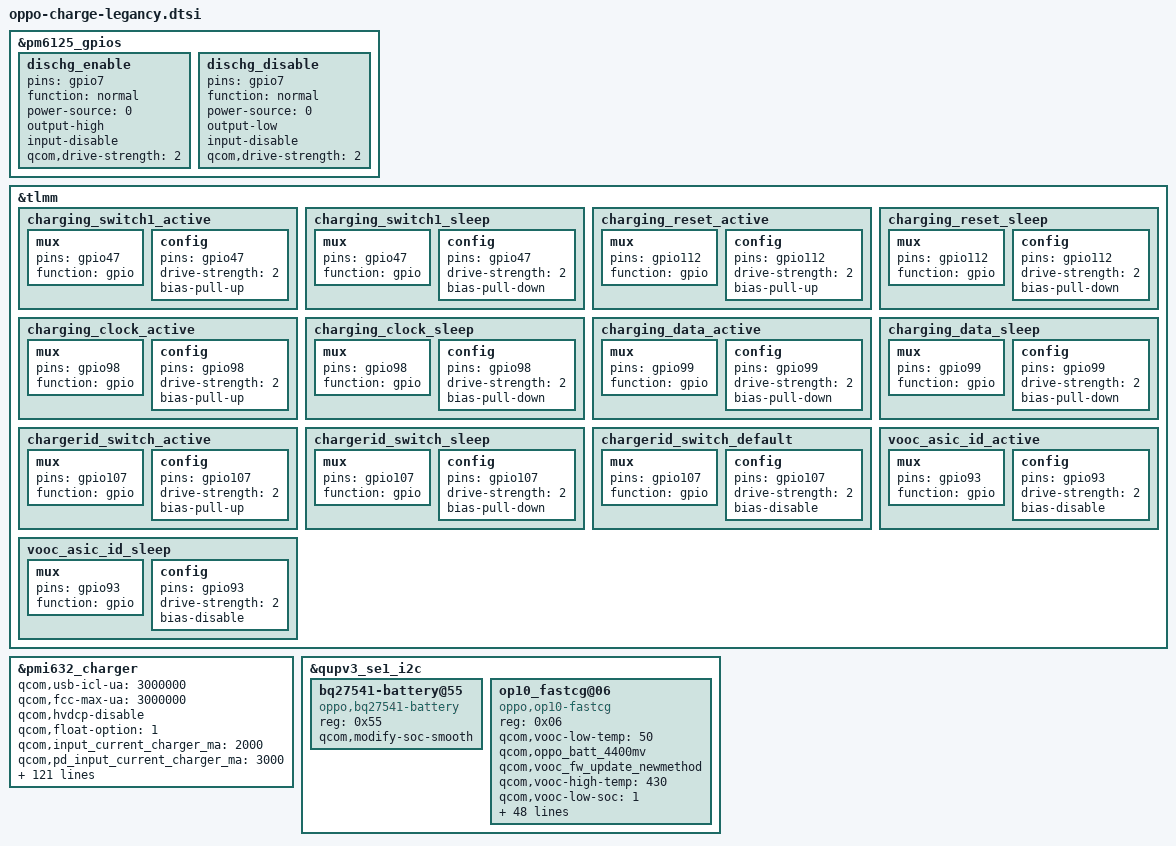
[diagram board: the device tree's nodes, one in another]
/**********************************************************************************
* Copyright (c)  2008-2019  Guangdong OPPO Mobile Comm Corp., Ltd
* VENDOR_EDIT
* Description: OPPO Charge Module Device Tree
*
* Version: 1.0
* Date: 2019-06-10
* Author: Yichun.Chen
*
* ------------------------------ Revision History: --------------------------------
* <version>           <date>                <author>                            <desc>
* Revision 1.0       2019-06-10            Yichun.Chen             Created for new architecture
***********************************************************************************/
&pm6125_gpios {
	dischg_enable: dischg_enable {
		pins = "gpio7";
		function = "normal";
		power-source = <0>;
		output-high;
		input-disable;
		qcom,drive-strength = <2>;
	};

	dischg_disable: dischg_disable {
		pins = "gpio7";
		function = "normal";
		power-source = <0>;
		output-low;
		input-disable;
		qcom,drive-strength = <2>;
	};
};

&tlmm {
			charging_switch1_active: charging_switch1_active {
				mux {
					pins = "gpio47";
					function = "gpio";
				};

				config {
					pins = "gpio47";
					drive-strength = <2>;
					bias-pull-up;
				};
			};

			charging_switch1_sleep: charging_switch1_sleep {
				mux {
					pins = "gpio47";
					function = "gpio";
				};

				config {
					pins = "gpio47";
					drive-strength = <2>;
					bias-pull-down;
				};
			};

			charging_reset_active: charging_reset_active {
				mux {
					pins = "gpio112";
					function = "gpio";
				};

				config {
					pins = "gpio112";
					drive-strength = <2>;
					bias-pull-up;
				};
			};

			charging_reset_sleep: charging_reset_sleep {
				mux {
					pins = "gpio112";
					function = "gpio";
				};

				config {
					pins = "gpio112";
					drive-strength = <2>;
					bias-pull-down;
				};
			};

			charging_clock_active: charging_clock_active {
				mux {
					pins = "gpio98";
					function = "gpio";
				};

				config {
					pins = "gpio98";
					drive-strength = <2>;
					bias-pull-up;
				};
			};

			charging_clock_sleep: charging_clock_sleep {
				mux {
					pins = "gpio98";
					function = "gpio";
				};

				config {
					pins = "gpio98";
					drive-strength = <2>;
					bias-pull-down;
				};
			};

			charging_data_active: charging_data_active {
				mux {
					pins = "gpio99";
					function = "gpio";
				};

				config {
					pins = "gpio99";
					drive-strength = <2>;
					bias-pull-down;
				};
			};

			charging_data_sleep: charging_data_sleep {
				mux {
					pins = "gpio99";
					function = "gpio";
				};

				config {
					pins = "gpio99";
					drive-strength = <2>;
					bias-pull-down;
				};
			};

			chargerid_switch_active: chargerid_switch_active {
				mux {
					pins = "gpio107";
					function = "gpio";
				};

				config {
					pins = "gpio107";
					drive-strength = <2>;
					bias-pull-up;
				};
			};

			chargerid_switch_sleep: chargerid_switch_sleep {
				mux {
					pins = "gpio107";
					function = "gpio";
				};

				config {
					pins = "gpio107";
					drive-strength = <2>;
					bias-pull-down;
				};
			};

			chargerid_switch_default: chargerid_switch_default {
				mux {
					pins = "gpio107";
					function = "gpio";
				};

				config {
					pins = "gpio107";
					drive-strength = <2>;
					bias-disable; /* NO PULL */
				};
			};
//#ifdef ODM_HQ_EDIT
/*zoutao@ODM_HQ.Charge add rk826 vooc 2020/06/10*/
			vooc_asic_id_active: vooc_asic_id_active {
				mux {
					pins = "gpio93";
					function = "gpio";
				};

				config {
					pins = "gpio93";
					drive-strength = <2>;
					bias-disable; /* NO PULL */
				};
			};

			vooc_asic_id_sleep: vooc_asic_id_sleep {
				mux {
					pins = "gpio93";
					function = "gpio";
				};

				config {
					pins = "gpio93";
					drive-strength = <2>;
					bias-disable; /* NO PULL */
				};
			};
//#endif
};

&pmi632_charger {

	//test_bob-supply = <&pm8150a_bob>;
	qcom,usb-icl-ua = <3000000>;
	qcom,fcc-max-ua = <3000000>;
	//qcom,fv-max-uv = <4373000>;
	qcom,hvdcp-disable;
	//io-channels = <&pm8150b_vadc ADC_GPIO3>;
	//io-channel-names = "chgID_voltage_adc";
	//qcom,otg-cl-ua = <2000000>;
	qcom,float-option = <1>;

	//for oppo chg framework:
	qcom,input_current_charger_ma = <2000>;
	qcom,pd_input_current_charger_ma = <3000>;
	qcom,input_current_usb_ma = <500>;

	qcom,input_current_led_ma = <1200>;
	qcom,input_current_led_ma_high = <1200>;
	qcom,input_current_led_ma_warm = <1500>;
	qcom,input_current_led_ma_normal = <2000>;

	qcom,input_current_camera_ma = <1200>;
	qcom,input_current_cdp_ma = <1500>;
	//qcom,input_current_led_ma_overtemp = <900>;
	qcom,overtemp_bat_decidegc = <350>;
	qcom,iterm_disabled = <0>;
	sw_full_count = <25>;
	qcom,iterm_ma = <210>;
	qcom,recharge-mv = <100>;
	qcom,batt_capacity_mah = <4015>;/*typical capacity*/
	//qcom,batt_capacity_mah = <3950>; /*rated capacity*/

	qcom,removed_bat_decidegc = <190>;	/* < -19C */

	qcom,cold_bat_decidegc = <20>;		/* -2C ~ 0C */
	qcom,temp_cold_vfloat_mv = <3980>;
	qcom,temp_cold_fastchg_current_ma = <314>;

	qcom,little_cold_bat_decidegc = <0>;	/* 0C ~ 5C */
	qcom,temp_little_cold_vfloat_mv = <4435>;
	qcom,temp_little_cold_fastchg_current_ma_high = <2200>;
	qcom,temp_little_cold_fastchg_current_ma_low = <1850>;
	qcom,pd_temp_little_cold_fastchg_current_ma_high = <2650>;
	qcom,pd_temp_little_cold_fastchg_current_ma_low = <1850>;
	qcom,temp_little_cold_fastchg_current_ma = <1850>;

	qcom,cool_bat_decidegc = <50>;		/* 5C~12C */
	qcom,temp_cool_vfloat_mv = <4435>;
	qcom,temp_cool_fastchg_current_ma_high = <2200>;
	qcom,temp_cool_fastchg_current_ma_low = <2200>;
	qcom,pd_temp_cool_fastchg_current_ma_high = <3300>;
	qcom,pd_temp_cool_fastchg_current_ma_low = <2650>;

	qcom,little_cool_bat_decidegc = <120>;	/*12C~16C*/
	qcom,temp_little_cool_vfloat_mv = <4435>;
	qcom,temp_little_cool_fastchg_current_ma = <2200>;
	qcom,pd_temp_little_cool_fastchg_current_ma = <3300>;

	qcom,normal_bat_decidegc = <160>;	/*16C~44C*/
	qcom,temp_normal_fastchg_current_ma = <2200>;
	qcom,pd_temp_normal_fastchg_current_ma = <3300>;
	qcom,temp_normal_vfloat_mv = <4435>;

	qcom,warm_bat_decidegc = <450>;		/*44C~53C*/ /*8pin Bat Vooc project need add 3 degree C*/
	qcom,temp_warm_vfloat_mv = <4130>;
	qcom,temp_warm_fastchg_current_ma = <1100>;
	qcom,pd_temp_warm_fastchg_current_ma = <1100>;
	qcom,temp_warm_fastchg_current_ma_led_on = <500>;

	qcom,hot_bat_decidegc = <530>;

	qcom,non_standard_vfloat_mv = <3980>;
	qcom,non_standard_fastchg_current_ma = <512>;
	qcom,short_c_bat_cv_mv = <4330>;
	qcom,short_c_bat_vfloat_mv = <3800>;
	qcom,short_c_bat_fastchg_current_ma = <512>;

	qcom,cold_vfloat_sw_limit = <3980>;
	qcom,little_cold_vfloat_sw_limit = <4385>;
	qcom,cool_vfloat_sw_limit = <4385>;
	qcom,little_cool_vfloat_sw_limit = <4385>;
	qcom,normal_vfloat_sw_limit = <4385>;
	qcom,warm_vfloat_sw_limit = <4130>;
	qcom,non_standard_vfloat_sw_limit = <3930>;
	qcom,short_c_bat_vfloat_sw_limit = <3750>;

	qcom,max_chg_time_sec = <57600>;
	qcom,charger_hv_thr = <5900>;
	qcom,charger_recv_thr = <5500>;
	qcom,charger_lv_thr = <3400>;
	qcom,vbatt_full_thr = <4400>;
	qcom,vbatt_hv_thr = <4550>;
	qcom,vfloat_step_mv = <8>;
	qcom,non_standard_vfloat_over_sw_limit = <3990>;
	qcom,cold_vfloat_over_sw_limit = <3990>;
	qcom,little_cold_vfloat_over_sw_limit = <4445>;
	qcom,cool_vfloat_over_sw_limit = <4445>;
	qcom,little_cool_vfloat_over_sw_limit = <4445>;
	qcom,normal_vfloat_over_sw_limit = <4445>;
	qcom,warm_vfloat_over_sw_limit = <4140>;

	qcom,vbatt_power_off = <3300>;
	qcom,vbatt_soc_1 = <3410>;
	qcom,vooc_project = <1>;
	qcom,vbatt_num = <1>;
	//qcom,new_ui_warning_support;
	qcom,ffc_support;

	qcom,normal_vterm_hw_inc = <18>;
	qcom,non_normal_vterm_hw_inc = <18>;

	qcom,ff1_normal_fastchg_ma = <1500>;
	qcom,ff1_exit_step_ma = <550>;
	qcom,ff1_warm_exit_step_ma = <500>;
	qcom,ffc2_normal_fastchg_ma = <1100>;/*12C~35c*/
	qcom,ffc2_temp_warm_decidegc = <350>;
	qcom,ffc2_warm_fastchg_ma = <1150>;/*35C~40c*/
	qcom,ffc2_temp_high_decidegc = <400>;
	qcom,ffc2_temp_low_decidegc = <120>;
	qcom,ffc2_exit_step_ma = <150>;

	qcom,ffc_normal_vfloat_sw_limit = <4475>;
	qcom,ffc_temp_normal_vfloat_mv = <4550>;
	qcom,ffc_normal_vfloat_over_sw_limit = <4550>;

	qcom,default_iterm_ma = <210>;
	qcom,default_temp_normal_fastchg_current_ma = <2200>;
	qcom,default_normal_vfloat_sw_limit = <4385>;
	qcom,default_temp_normal_vfloat_mv = <4435>;
	qcom,default_normal_vfloat_over_sw_limit = <4445>;

	qcom,default_temp_little_cool_fastchg_current_ma = <2200>;
	qcom,default_little_cool_vfloat_sw_limit = <4385>;
	qcom,default_temp_little_cool_vfloat_mv = <4435>;
	qcom,default_little_cool_vfloat_over_sw_limit = <4445>;

	///qcom,offset_temp = <30>;
	//for control:
	//qcom,suspend_after_full;
	qcom,check_batt_full_by_sw;
	qcom,external_gauge;
	qcom,chg_ctrl_by_lcd;
	qcom,chg_ctrl_by_camera;
	qcom,sw_vfloat_over_protect_enable;
	qcom,lpd-disable;

	qcom,chargerid_switch-gpio = <&tlmm 107 0x00>;
	qcom,dischg-gpio = <&pm6125_gpios 7 0x00>;

	pinctrl-names = "chargerid_switch_active", "chargerid_switch_sleep", "chargerid_switch_default",
					"dischg_enable", "dischg_disable";

	pinctrl-0 = <&chargerid_switch_active>;
	pinctrl-1 = <&chargerid_switch_sleep>;
	pinctrl-2 = <&chargerid_switch_default>;
	pinctrl-3 = <&dischg_enable>;
	pinctrl-4 = <&dischg_disable>;
};

&qupv3_se1_i2c {
	status = "okay";
	//qcom,clk-freq-out = <100000>;

	bq27541-battery@55 {
		status = "okay";
		compatible = "oppo,bq27541-battery";
		reg = <0x55>;
		qcom,modify-soc-smooth;
		//qcom,battery-full-param;//only for wite battery full param in guage dirver probe on 7250 platform
	};

	op10_fastcg@06{
		status = "okay";
		compatible = "oppo,op10-fastcg";
		reg = <0x06>;
		qcom,vooc-low-temp = <50>;
		qcom,oppo_batt_4400mv;
//#ifdef ODM_HQ_EDIT
/*zoutao@ODM_HQ.Charge vooc firmware update newmethod 2020/07/08*/
		qcom,vooc_fw_update_newmethod;
//#endif
		///qcom,vooc-fw-type = <0x22>;//5A
		qcom,vooc-high-temp = <430>;
		qcom,vooc-low-soc = <1>;
		qcom,vooc-high-soc = <85>;
		qcom,vooc-fw-type = <3>;

		qcom,vooc_multistep_adjust_current_support;
		qcom,vooc_multistep_initial_batt_temp = <1000>;
		qcom,vooc_strategy_normal_current = <0x06>;

		qcom,vooc-normal-to-little-cool-current = <0x04>;
		qcom,vooc_strategy1_batt_high_temp0 = <400>;
		qcom,vooc_strategy1_batt_high_temp1 = <425>;
		qcom,vooc_strategy1_batt_high_temp2 = <435>;
		qcom,vooc_strategy1_batt_low_temp2 = <430>;
		qcom,vooc_strategy1_batt_low_temp1 = <410>;
		qcom,vooc_strategy1_batt_low_temp0 = <390>;

		qcom,vooc_strategy1_high_current0 = <0x04>;//4A
		qcom,vooc_strategy1_high_current1 = <0x03>;//3A
		qcom,vooc_strategy1_high_current2 = <0x02>;//2A
		qcom,vooc_strategy1_low_current2 = <0x03>;//3A
		qcom,vooc_strategy1_low_current1 = <0x05>;//5A
		qcom,vooc_strategy1_low_current0 = <0x06>;//6A

		qcom,vooc_strategy2_batt_up_temp1 = <370>;
		qcom,vooc_strategy2_batt_up_down_temp2 = <380>;
		qcom,vooc_strategy2_batt_up_temp3 = <390>;
		qcom,vooc_strategy2_batt_up_down_temp4 = <395>;
		qcom,vooc_strategy2_batt_up_temp5 = <400>;
		qcom,vooc_strategy2_batt_up_temp6 = <415>;
		qcom,vooc_strategy2_high0_current = <0x06>;
		qcom,vooc_strategy2_high1_current = <0x06>;
		qcom,vooc_strategy2_high2_current = <0x06>;
		qcom,vooc_strategy2_high3_current = <0x06>;

		pinctrl-names = "switch1_act_switch2_act", "switch1_sleep_switch2_sleep",
						"switch1_act_switch3_act", "switch1_sleep_switch3_sleep",
						"switch1_act_switch2_sleep", "switch1_sleep_switch2_act",
						"clock_active","clock_sleep",
						"data_active","data_sleep",
						"reset_active","reset_sleep",
						"vooc_asic_id_active","vooc_asic_id_sleep";
		pinctrl-0 = <&charging_switch1_active>;
		pinctrl-1 = <&charging_switch1_sleep >;
		pinctrl-2 = <&charging_switch1_active>;
		pinctrl-3 = <&charging_switch1_sleep >;
		pinctrl-4 = <&charging_switch1_active>;
		pinctrl-5 = <&charging_switch1_sleep>;
		pinctrl-6 = <&charging_clock_active >;
		pinctrl-7 = <&charging_clock_sleep >;
		pinctrl-8 = <&charging_data_active >;
		pinctrl-9 = <&charging_data_sleep >;
		pinctrl-10 = <&charging_reset_active >;
		pinctrl-11 = <&charging_reset_sleep >;
		pinctrl-12 = <&vooc_asic_id_active >;
		pinctrl-13 = <&vooc_asic_id_sleep >;

		qcom,charging_switch1-gpio = <&tlmm 47 0x00>;
		qcom,charging_switch1_ctr1-gpio = <&tlmm 52 0x00>;
		//qcom,charging_switch2-gpio = <&tlmm 113 0x00>;
		//qcom,charging_switch3-gpio = <&tlmm 38 0x00>;

		qcom,charging_reset-gpio = <&tlmm 112 0x00>;
		qcom,charging_clock-gpio = <&tlmm 98 0x00>;
		qcom,charging_data-gpio = <&tlmm 99 0x00>;
		qcom,vooc_asic_id-gpio = <&tlmm 93 0x00>;

	};
};
